# ATtiny1634 register map
Vendor: Atmel; File version: 1.0
CPU: other r0p0, little endian, no MPU, no FPU, 4 interrupt priority bits
Registers are 8-bit, read-write, reset 0x0 unless marked. A register's access mark holds for its fields unless they carry their own. Offsets are from the block's base; [hi:lo] are bit positions.

## LOCKBIT — Lockbits
Base 0x00800000
0x00 LOCKBIT
  [1:0] LB — Memory Lock
    0=PROG_VER_DISABLED (Further programming and verification disabled); 2=PROG_DISABLED (Further programming disabled); 3=NO_LOCK (No memory lock features enabled)

## PORTA — I/O Port
Base 0x0080002F
0x00 PINA — Port A Input Pins
0x01 DDRA — Data Direction Register, Port A
0x02 PORTA — Port A Data Register
0x03 PUEA — Pull-up Enable Control Register
  [7:0] PUEA — Pull-up Enable Control bit
0x04 PORTCR — Port Control Register
  [0] BBMA — Break-Before-Make Mode Enable

## PORTB — I/O Port
Base 0x0080002B
0x00 PINB — Port B Data register
0x01 DDRB — Data Direction Register, Port B
0x02 PORTB — Input Pins, Port B
0x03 PUEB — Pull-up Enable Control Register
  [3:0] PUEB — Pull-up Enable Control bit
0x08 PORTCR — Port Control Register
  [1] BBMB — Break-Before-Make Mode Enable

## PORTC — I/O Port
Base 0x00800027
0x00 PINC — Port C Input Pins
0x01 DDRC — Data Direction Register, Port C
0x02 PORTC — Port C Data Register
0x03 PUEC — Pull-up Enable Control Register
  [5:0] PUEC — Pull-up Enable Control bit
0x0C PORTCR — Port Control Register
  [2] BBMC — Break-Before-Make Mode Enable

## TC0 — Timer/Counter, 8-bit
Base 0x00800037
0x00 OCR0B — Timer/Counter0 Output Compare Register
0x01 OCR0A — Timer/Counter0 Output Compare Register
0x02 TCNT0 — Timer/Counter0
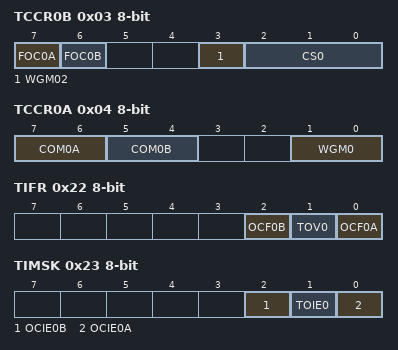
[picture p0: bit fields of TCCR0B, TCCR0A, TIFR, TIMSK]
0x03 TCCR0B — Timer/Counter Control Register B
  [7] FOC0A — Force Output Compare B
  [6] FOC0B — Force Output Compare B
  [3] WGM02
  [2:0] CS0 — Clock Select
    0=NO_CLOCK_SOURCE_STOPPED; 1=RUNNING_NO_PRESCALING; 2=RUNNING_CLK_8; 3=RUNNING_CLK_64; 4=RUNNING_CLK_256; 5=RUNNING_CLK_1024; 6=RUNNING_EXTCLK_TN_FALLING_EDGE; 7=RUNNING_EXTCLK_TN_RISING_EDGE
0x04 TCCR0A — Timer/Counter Control Register A
  [7:6] COM0A — Compare Match Output A Mode
  [5:4] COM0B — Compare Match Output B Mode
  [1:0] WGM0 — Waveform Generation Mode
0x22 TIFR — Timer/Counter Interrupt Flag register (read-only for debugger)
  [2] OCF0B — Timer/Counter0 Output Compare Flag 0B
  [1] TOV0 — Timer/Counter0 Overflow Flag
  [0] OCF0A — Timer/Counter0 Output Compare Flag 0A
0x23 TIMSK — Timer/Counter Interrupt Mask Register
  [2] OCIE0B — Timer/Counter0 Output Compare Match B Interrupt Enable
  [1] TOIE0 — Timer/Counter0 Overflow Interrupt Enable
  [0] OCIE0A — Timer/Counter0 Output Compare Match A Interrupt Enable
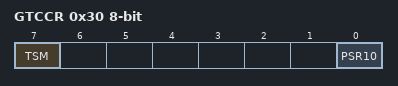
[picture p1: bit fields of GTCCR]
0x30 GTCCR — General Timer/Counter Control Register
  [7] TSM — Timer/Counter Synchronization Mode
  [0] PSR10 — Prescaler Reset Timer/Counter1 and Timer/Counter0

## TC1 — Timer/Counter, 16-bit
Base 0x00800059
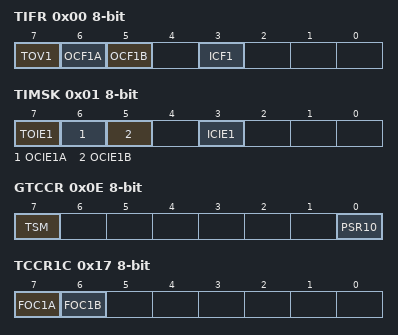
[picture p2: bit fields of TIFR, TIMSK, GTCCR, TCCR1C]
0x00 TIFR — Timer/Counter Interrupt Flag register (read-only for debugger)
  [7] TOV1 — Timer/Counter1 Overflow Flag
  [6] OCF1A — Output Compare Flag 1A
  [5] OCF1B — Output Compare Flag 1B
  [3] ICF1 — Input Capture Flag 1
0x01 TIMSK — Timer/Counter Interrupt Mask Register
  [7] TOIE1 — Timer/Counter1 Overflow Interrupt Enable
  [6] OCIE1A — Timer/Counter1 Output CompareA Match Interrupt Enable
  [5] OCIE1B — Timer/Counter1 Output CompareB Match Interrupt Enable
  [3] ICIE1 — Timer/Counter1 Input Capture Interrupt Enable
0x0E GTCCR — General Timer/Counter Control Register
  [7] TSM — Timer/Counter Synchronization Mode
  [0] PSR10 — Prescaler Reset Timer/Counter1 and Timer/Counter0
0x0F ICR1 16-bit (reset mask 0xFF) — Timer/Counter1 Input Capture Register Bytes
0x11 OCR1B 16-bit (reset mask 0xFF) — Timer/Counter1 Output Compare Register Bytes
0x13 OCR1A 16-bit (reset mask 0xFF) — Timer/Counter1 Output Compare Register Bytes
0x15 TCNT1 16-bit (reset mask 0xFF) — Timer/Counter1 Bytes
0x17 TCCR1C — Timer/Counter1 Control Register C (read-only for debugger)
  [7] FOC1A — Force Output Compare for Channel A
  [6] FOC1B — Force Output Compare for Channel B
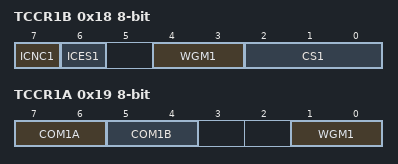
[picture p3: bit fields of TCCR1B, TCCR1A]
0x18 TCCR1B — Timer/Counter1 Control Register B
  [7] ICNC1 — Input Capture 1 Noise Canceler
  [6] ICES1 — Input Capture 1 Edge Select
  [4:3] WGM1 — Waveform Generation Mode Bits
  [2:0] CS1 — Clock Select1 bits
    0=NO_CLOCK_SOURCE_STOPPED; 1=RUNNING_NO_PRESCALING; 2=RUNNING_CLK_8; 3=RUNNING_CLK_64; 4=RUNNING_CLK_256; 5=RUNNING_CLK_1024; 6=RUNNING_EXTCLK_TN_FALLING_EDGE; 7=RUNNING_EXTCLK_TN_RISING_EDGE
0x19 TCCR1A — Timer/Counter1 Control Register A
  [7:6] COM1A — Compare Output Mode 1A, bits
  [5:4] COM1B — Compare Output Mode 1B, bits
  [1:0] WGM1 — Pulse Width Modulator Select Bits
